# STM32H7B3x register map
File version: 2.0
CPU: CM7 r0p1, little endian, MPU, FPU, 4 interrupt priority bits
Registers are 32-bit, read-write, reset 0x0 unless marked. A register's access mark holds for its fields unless they carry their own. Offsets are from the block's base; [hi:lo] are bit positions; {n}, {i} and the like mark numbered series; 'fields as' and 'values as' point back to an identical list.

## HSEM
Base 0x48020800
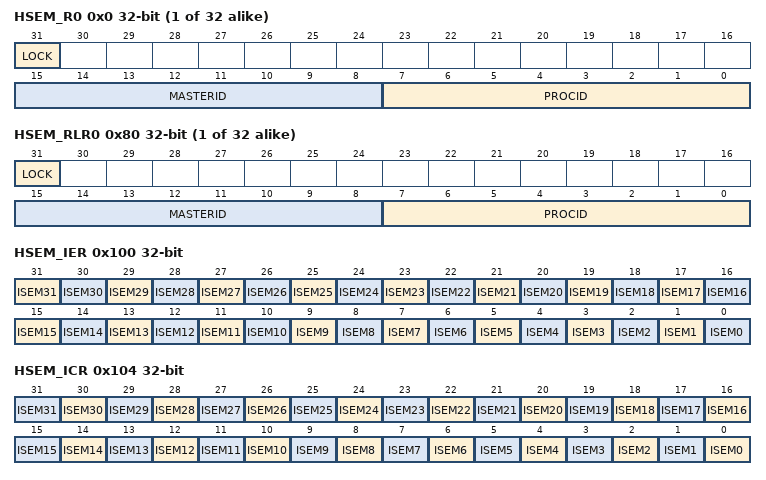
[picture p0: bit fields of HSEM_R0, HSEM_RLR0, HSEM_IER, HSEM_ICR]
{0x0+4i} HSEM_R{i} (i=0..31) — HSEM register HSEM_R0 HSEM_R31
  [31] LOCK — Lock indication
  [15:8] MASTERID — Semaphore MasterID
  [7:0] PROCID — Semaphore ProcessID
{0x80+4i} HSEM_RLR{i} ro (i=0..31) — HSEM Read lock register
  fields as HSEM_R0
0x100 HSEM_IER — HSEM Interrupt enable register
  [31] ISEM31 — Interrupt(N) semaphore n enable bit.
  [n] ISEM{n} (n=0..30) — Interrupt semaphore n enable bit
0x104 HSEM_ICR ro — HSEM Interrupt clear register
  [n] ISEM{n} (n=0..31) — Interrupt(N) semaphore n clear bit
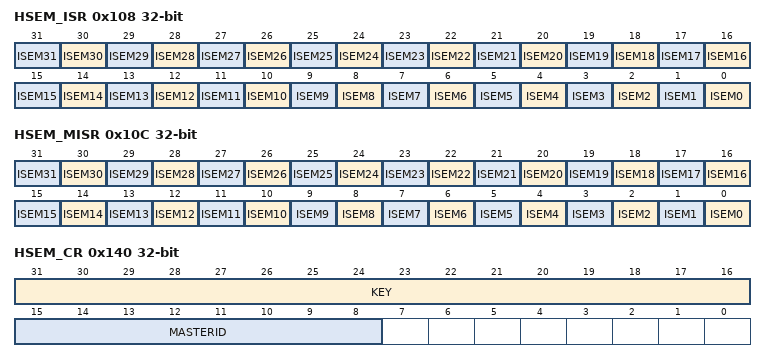
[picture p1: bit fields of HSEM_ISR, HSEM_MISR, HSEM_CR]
0x108 HSEM_ISR ro — HSEM Interrupt status register
  [n] ISEM{n} (n=0..31) — Interrupt(N) semaphore n status bit before enable (mask)
0x10C HSEM_MISR ro — HSEM Masked interrupt status register
  [n] ISEM{n} (n=0..31) — masked interrupt(N) semaphore n status bit after enable (mask)
0x140 HSEM_CR — HSEM Clear register
  [31:16] KEY — Semaphore clear Key
  [15:8] MASTERID — MasterID of semaphores to be cleared
0x144 HSEM_KEYR — HSEM Interrupt clear register
  [31:16] KEY — Semaphore Clear Key

## LPTIM1 — Low power timer
Base 0x40002400
Same registers: LPTIM2 0x58002400
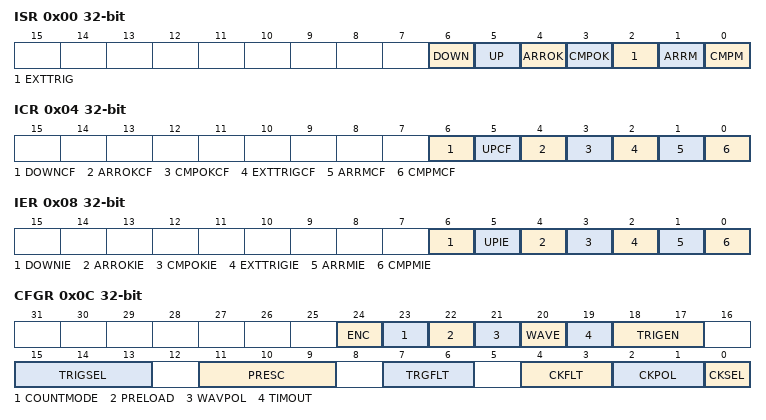
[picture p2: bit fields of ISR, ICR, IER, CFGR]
0x00 ISR ro — Interrupt and Status Register
  [6] DOWN — Counter direction change up to down
  [5] UP — Counter direction change down to up
  [4] ARROK — Autoreload register update OK
  [3] CMPOK — Compare register update OK
  [2] EXTTRIG — External trigger edge event
  [1] ARRM — Autoreload match
  [0] CMPM — Compare match
0x04 ICR wo — Interrupt Clear Register
  [6] DOWNCF — Direction change to down Clear Flag
  [5] UPCF — Direction change to UP Clear Flag
  [4] ARROKCF — Autoreload register update OK Clear Flag
  [3] CMPOKCF — Compare register update OK Clear Flag
  [2] EXTTRIGCF — External trigger valid edge Clear Flag
  [1] ARRMCF — Autoreload match Clear Flag
  [0] CMPMCF — compare match Clear Flag
0x08 IER — Interrupt Enable Register
  [6] DOWNIE — Direction change to down Interrupt Enable
  [5] UPIE — Direction change to UP Interrupt Enable
  [4] ARROKIE — Autoreload register update OK Interrupt Enable
  [3] CMPOKIE — Compare register update OK Interrupt Enable
  [2] EXTTRIGIE — External trigger valid edge Interrupt Enable
  [1] ARRMIE — Autoreload match Interrupt Enable
  [0] CMPMIE — Compare match Interrupt Enable
0x0C CFGR — Configuration Register
  [24] ENC — Encoder mode enable
  [23] COUNTMODE — counter mode enabled
  [22] PRELOAD — Registers update mode
  [21] WAVPOL — Waveform shape polarity
  [20] WAVE — Waveform shape
  [19] TIMOUT — Timeout enable
  [18:17] TRIGEN — Trigger enable and polarity
  [15:13] TRIGSEL — Trigger selector
  [11:9] PRESC — Clock prescaler
  [7:6] TRGFLT — Configurable digital filter for trigger
  [4:3] CKFLT — Configurable digital filter for external clock
  [2:1] CKPOL — Clock Polarity
  [0] CKSEL — Clock selector
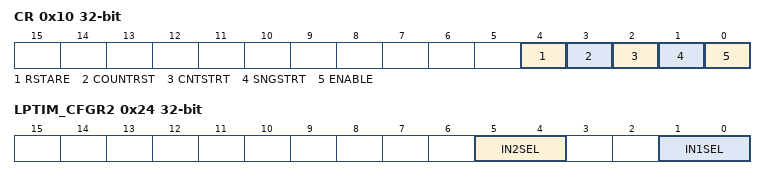
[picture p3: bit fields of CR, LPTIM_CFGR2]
0x10 CR — Control Register
  [4] RSTARE — Reset after read enable
  [3] COUNTRST — Counter reset
  [2] CNTSTRT — Timer start in continuous mode
  [1] SNGSTRT — LPTIM start in single mode
  [0] ENABLE — LPTIM Enable
0x14 CMP — Compare Register
  [15:0] CMP — Compare value
0x18 ARR reset 0x1 — Autoreload Register
  [15:0] ARR — Auto reload value
0x1C CNT ro — Counter Register
  [15:0] CNT — Counter value
0x24 LPTIM_CFGR2 — LPTIM configuration register 2
  [5:4] IN2SEL — LPTIM Input 2 selection
  [1:0] IN1SEL — LPTIM Input 1 selection

## LPTIM3 — Low power timer
Base 0x58002800
Registers as LPTIM1; these are added or differ:
0x24 LPTIM_CFGR2 — LPTIM configuration register 2
  [1:0] IN1SEL — LPTIM Input 1 selection

## LPUART1
Base 0x58000C00
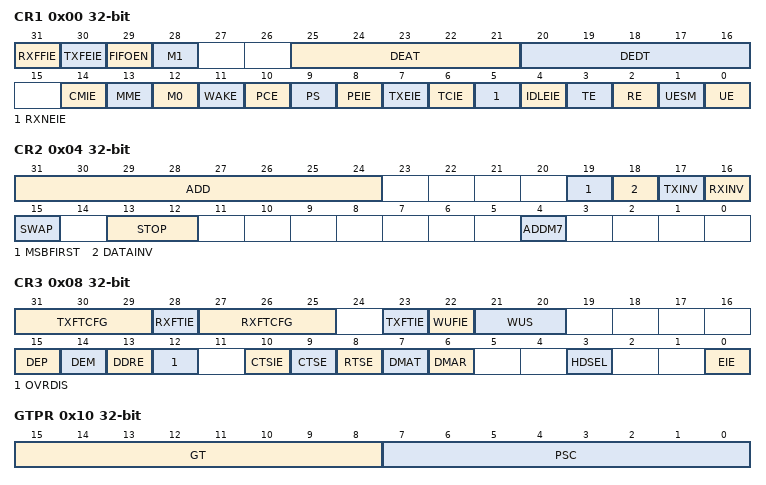
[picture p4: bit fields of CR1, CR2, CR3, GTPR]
0x00 CR1 — Control register 1
  [31] RXFFIE — RXFIFO Full interrupt enable
  [30] TXFEIE — TXFIFO empty interrupt enable
  [29] FIFOEN — FIFO mode enable
  [28] M1 — Word length
  [25:21] DEAT — Driver Enable assertion time
  [20:16] DEDT — Driver Enable deassertion time
  [14] CMIE — Character match interrupt enable
  [13] MME — Mute mode enable
  [12] M0 — Word length
  [11] WAKE — Receiver wakeup method
  [10] PCE — Parity control enable
  [9] PS — Parity selection
  [8] PEIE — PE interrupt enable
  [7] TXEIE — interrupt enable
  [6] TCIE — Transmission complete interrupt enable
  [5] RXNEIE — RXNE interrupt enable
  [4] IDLEIE — IDLE interrupt enable
  [3] TE — Transmitter enable
  [2] RE — Receiver enable
  [1] UESM — USART enable in Stop mode
  [0] UE — USART enable
0x04 CR2 — Control register 2
  [31:24] ADD — Address of the USART node
  [19] MSBFIRST — Most significant bit first
  [18] DATAINV — Binary data inversion
  [17] TXINV — TX pin active level inversion
  [16] RXINV — RX pin active level inversion
  [15] SWAP — Swap TX/RX pins
  [13:12] STOP — STOP bits
  [4] ADDM7 — 7-bit Address Detection/4-bit Address Detection
0x08 CR3 — Control register 3
  [31:29] TXFTCFG — TXFIFO threshold configuration
  [28] RXFTIE — RXFIFO threshold interrupt enable
  [27:25] RXFTCFG — Receive FIFO threshold configuration
  [23] TXFTIE — TXFIFO threshold interrupt enable
  [22] WUFIE — Wakeup from Stop mode interrupt enable
  [21:20] WUS — Wakeup from Stop mode interrupt flag selection
  [15] DEP — Driver enable polarity selection
  [14] DEM — Driver enable mode
  [13] DDRE — DMA Disable on Reception Error
  [12] OVRDIS — Overrun Disable
  [10] CTSIE — CTS interrupt enable
  [9] CTSE — CTS enable
  [8] RTSE — RTS enable
  [7] DMAT — DMA enable transmitter
  [6] DMAR — DMA enable receiver
  [3] HDSEL — Half-duplex selection
  [0] EIE — Error interrupt enable
0x0C BRR — Baud rate register
  [19:0] BRR
0x10 GTPR — Guard time and prescaler register
  [15:8] GT — Guard time value
  [7:0] PSC — Prescaler value
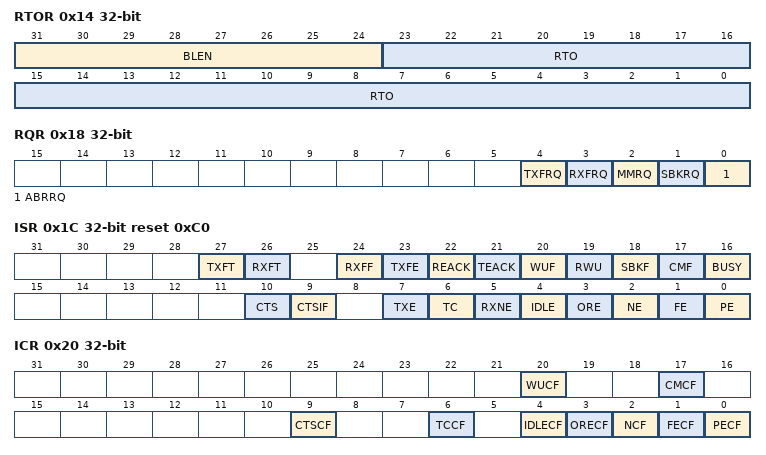
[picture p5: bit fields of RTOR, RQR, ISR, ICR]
0x14 RTOR — Receiver timeout register
  [31:24] BLEN — Block Length
  [23:0] RTO — Receiver timeout value
0x18 RQR wo — Request register
  [4] TXFRQ — Transmit data flush request
  [3] RXFRQ — Receive data flush request
  [2] MMRQ — Mute mode request
  [1] SBKRQ — Send break request
  [0] ABRRQ — Auto baud rate request
0x1C ISR ro reset 0xC0 — Interrupt & status register
  [27] TXFT — TXFIFO threshold flag
  [26] RXFT — RXFIFO threshold flag
  [24] RXFF — RXFIFO Full
  [23] TXFE — TXFIFO Empty
  [22] REACK
  [21] TEACK
  [20] WUF
  [19] RWU
  [18] SBKF
  [17] CMF
  [16] BUSY
  [10] CTS
  [9] CTSIF
  [7] TXE
  [6] TC
  [5] RXNE
  [4] IDLE
  [3] ORE
  [2] NE
  [1] FE
  [0] PE
0x20 ICR wo — Interrupt flag clear register
  [20] WUCF — Wakeup from Stop mode clear flag
  [17] CMCF — Character match clear flag
  [9] CTSCF — CTS clear flag
  [6] TCCF — Transmission complete clear flag
  [4] IDLECF — Idle line detected clear flag
  [3] ORECF — Overrun error clear flag
  [2] NCF — Noise detected clear flag
  [1] FECF — Framing error clear flag
  [0] PECF — Parity error clear flag
0x24 RDR ro — Receive data register
  [8:0] RDR — Receive data value
0x28 TDR — Transmit data register
  [8:0] TDR — Transmit data value
0x2C PRESC — Prescaler register
  [3:0] PRESCALER — Clock prescaler
